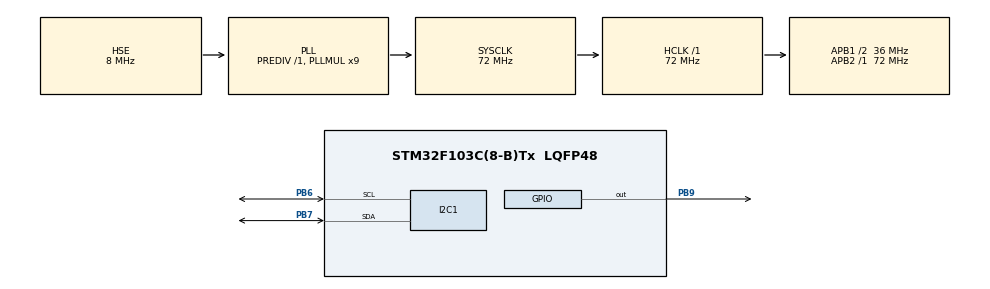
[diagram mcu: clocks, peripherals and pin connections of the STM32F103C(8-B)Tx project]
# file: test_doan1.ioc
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FREERTOS.Tasks01=clock_task,0,128,StartDefaultTask,Default,NULL,Dynamic,NULL,NULL;dht22_task,0,128,StartTask02,Default,NULL,Dynamic,NULL,NULL
I2C1.I2C_Mode=I2C_Fast
Mcu.Family=STM32F1
Mcu.Name=STM32F103C(8-B)Tx
Mcu.Package=LQFP48
NVIC.PriorityGroup=NVIC_PRIORITYGROUP_4
NVIC.TIM4_IRQn=true\:15\:0\:false\:false\:true\:false\:false\:true\:true
NVIC.TimeBase=TIM4_IRQn
NVIC.TimeBaseIP=TIM4
PA13.Mode=Serial_Wire
PA13.Signal=SYS_JTMS-SWDIO
PA14.Mode=Serial_Wire
PA14.Signal=SYS_JTCK-SWCLK
PB6.Mode=I2C
PB6.Signal=I2C1_SCL
PB7.Mode=I2C
PB7.Signal=I2C1_SDA
PB9.Signal=GPIO_Output
PD0-OSC_IN.Mode=HSE-External-Oscillator
PD0-OSC_IN.Signal=RCC_OSC_IN
PD1-OSC_OUT.Mode=HSE-External-Oscillator
PD1-OSC_OUT.Signal=RCC_OSC_OUT
ProjectManager.HeapSize=0x200
ProjectManager.StackSize=0x400
ProjectManager.TargetToolchain=MDK-ARM V5.32
RCC.AHBFreq_Value=72000000
RCC.APB1CLKDivider=RCC_HCLK_DIV2
RCC.APB1Freq_Value=36000000
RCC.APB1TimFreq_Value=72000000
RCC.APB2Freq_Value=72000000
RCC.APB2TimFreq_Value=72000000
RCC.HCLKFreq_Value=72000000
RCC.PLLMUL=RCC_PLL_MUL9
RCC.PLLSourceVirtual=RCC_PLLSOURCE_HSE
RCC.SYSCLKFreq_VALUE=72000000
RCC.SYSCLKSource=RCC_SYSCLKSOURCE_PLLCLK
RCC.USBFreq_Value=72000000
TIM1.Prescaler=71
VP_FREERTOS_VS_CMSIS_V1.Mode=CMSIS_V1
VP_RTC_No_RTC_Output.Mode=RTC_OUT_NO
VP_RTC_VS_RTC_Activate.Mode=RTC_Enabled
VP_RTC_VS_RTC_Calendar.Mode=RTC_Calendar
VP_SYS_VS_tim4.Mode=TIM4
VP_TIM1_VS_ClockSourceINT.Mode=Internal
board=custom

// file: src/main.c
/* USER CODE BEGIN Header */
/**
  ******************************************************************************
  * @file           : main.c
  * @brief          : Main program body
  ******************************************************************************
  * @attention
  *
  * Copyright (c) 2025 STMicroelectronics.
  * All rights reserved.
  *
  * This software is licensed under terms that can be found in the LICENSE file
  * in the root directory of this software component.
  * If no LICENSE file comes with this software, it is provided AS-IS.
  *
  ******************************************************************************
  */
/* USER CODE END Header */
#include "main.h"
#include "cmsis_os.h"
#include "fonts.h"
#include "ssd1306.h"
#include <stdio.h>
/* USER CODE BEGIN Includes */
#define DHT22_PORT GPIOB
#define DHT22_PIN GPIO_PIN_9
/* USER CODE END Includes */

I2C_HandleTypeDef hi2c1;

RTC_HandleTypeDef hrtc;

TIM_HandleTypeDef htim1;

osThreadId clock_taskHandle;
osThreadId dht22_taskHandle;

void SystemClock_Config(void);
static void MX_GPIO_Init(void);
static void MX_I2C1_Init(void);
static void MX_RTC_Init(void);
static void MX_TIM1_Init(void);
void StartDefaultTask(void const * argument);
void StartTask02(void const * argument);
/*--------------------------------------------------------*/
uint8_t RH1, RH2, TC1, TC2, SUM, CHECK;
uint32_t pMillis, cMillis;
float tCelsius = 0;
float RH = 0;
uint8_t RHI, RHD, TCI, TCD;
char strCopy[15];

void microDelay (uint16_t delay)
{
  __HAL_TIM_SET_COUNTER(&htim1, 0);
  while (__HAL_TIM_GET_COUNTER(&htim1) < delay);
}

uint8_t DHT22_Start (void)
{
  uint8_t Response = 0;
  GPIO_InitTypeDef GPIO_InitStructPrivate = {0};
  GPIO_InitStructPrivate.Pin = DHT22_PIN;
  GPIO_InitStructPrivate.Mode = GPIO_MODE_OUTPUT_PP;
  GPIO_InitStructPrivate.Speed = GPIO_SPEED_FREQ_LOW;
  GPIO_InitStructPrivate.Pull = GPIO_NOPULL;
  HAL_GPIO_Init(DHT22_PORT, &GPIO_InitStructPrivate); // set the pin as output
  HAL_GPIO_WritePin (DHT22_PORT, DHT22_PIN, GPIO_PIN_RESET);   // pull the pin low
  microDelay (1300);   // wait for 1300us
  HAL_GPIO_WritePin (DHT22_PORT, DHT22_PIN, GPIO_PIN_SET);   // pull the pin high
  microDelay (30);   // wait for 30us
  GPIO_InitStructPrivate.Mode = GPIO_MODE_INPUT;
  GPIO_InitStructPrivate.Pull = GPIO_PULLUP;
  HAL_GPIO_Init(DHT22_PORT, &GPIO_InitStructPrivate); // set the pin as input
  microDelay (40);
  if (!(HAL_GPIO_ReadPin (DHT22_PORT, DHT22_PIN)))
  {
    microDelay (80);
    if ((HAL_GPIO_ReadPin (DHT22_PORT, DHT22_PIN))) Response = 1;
  }
  pMillis = HAL_GetTick();
  cMillis = HAL_GetTick();
  while ((HAL_GPIO_ReadPin (DHT22_PORT, DHT22_PIN)) && pMillis + 2 > cMillis)
  {
    cMillis = HAL_GetTick();
  }
  return Response;
}

uint8_t DHT22_Read (void)
{
  uint8_t a,b;
  for (a=0;a<8;a++)
  {
    pMillis = HAL_GetTick();
    cMillis = HAL_GetTick();
    while (!(HAL_GPIO_ReadPin (DHT22_PORT, DHT22_PIN)) && pMillis + 2 > cMillis)
    {  // wait for the pin to go high
      cMillis = HAL_GetTick();
    }
    microDelay (40);   // wait for 40 us
    if (!(HAL_GPIO_ReadPin (DHT22_PORT, DHT22_PIN)))   // if the pin is low
      b&= ~(1<<(7-a));
    else
      b|= (1<<(7-a));
    pMillis = HAL_GetTick();
    cMillis = HAL_GetTick();
    while ((HAL_GPIO_ReadPin (DHT22_PORT, DHT22_PIN)) && pMillis + 2 > cMillis)
    {  // wait for the pin to go low
      cMillis = HAL_GetTick();
    }
  }
  return b;
}

int main(void)
{

  /* MCU Configuration--------------------------------------------------------*/

  /* Reset of all peripherals, Initializes the Flash interface and the Systick. */
  HAL_Init();

  /* Configure the system clock */
  SystemClock_Config();

  /* Initialize all configured peripherals */
  MX_GPIO_Init();
  MX_I2C1_Init();
  MX_RTC_Init();
  MX_TIM1_Init();
	SSD1306_Init();

  /* Create the thread(s) */
  /* definition and creation of clock_task */
  osThreadDef(clock_task, StartDefaultTask, osPriorityNormal, 0, 128);
  clock_taskHandle = osThreadCreate(osThread(clock_task), NULL);

  /* definition and creation of dht22_task */
  osThreadDef(dht22_task, StartTask02, osPriorityNormal, 0, 128);
  dht22_taskHandle = osThreadCreate(osThread(dht22_task), NULL);

  /* Start scheduler */
  osKernelStart();

  /* We should never get here as control is now taken by the scheduler */

  /* Infinite loop */
  while (1)
  {

  }
}

void SystemClock_Config(void)
{
  RCC_OscInitTypeDef RCC_OscInitStruct = {0};
  RCC_ClkInitTypeDef RCC_ClkInitStruct = {0};
  RCC_PeriphCLKInitTypeDef PeriphClkInit = {0};

  /** Initializes the RCC Oscillators according to the specified parameters
  * in the RCC_OscInitTypeDef structure.
  */
  RCC_OscInitStruct.OscillatorType = RCC_OSCILLATORTYPE_LSI|RCC_OSCILLATORTYPE_HSE;
  RCC_OscInitStruct.HSEState = RCC_HSE_ON;
  RCC_OscInitStruct.HSEPredivValue = RCC_HSE_PREDIV_DIV1;
  RCC_OscInitStruct.HSIState = RCC_HSI_ON;
  RCC_OscInitStruct.LSIState = RCC_LSI_ON;
  RCC_OscInitStruct.PLL.PLLState = RCC_PLL_ON;
  RCC_OscInitStruct.PLL.PLLSource = RCC_PLLSOURCE_HSE;
  RCC_OscInitStruct.PLL.PLLMUL = RCC_PLL_MUL9;
  if (HAL_RCC_OscConfig(&RCC_OscInitStruct) != HAL_OK)
  {
    Error_Handler();
  }

  /** Initializes the CPU, AHB and APB buses clocks
  */
  RCC_ClkInitStruct.ClockType = RCC_CLOCKTYPE_HCLK|RCC_CLOCKTYPE_SYSCLK
                              |RCC_CLOCKTYPE_PCLK1|RCC_CLOCKTYPE_PCLK2;
  RCC_ClkInitStruct.SYSCLKSource = RCC_SYSCLKSOURCE_PLLCLK;
  RCC_ClkInitStruct.AHBCLKDivider = RCC_SYSCLK_DIV1;
  RCC_ClkInitStruct.APB1CLKDivider = RCC_HCLK_DIV2;
  RCC_ClkInitStruct.APB2CLKDivider = RCC_HCLK_DIV1;

  if (HAL_RCC_ClockConfig(&RCC_ClkInitStruct, FLASH_LATENCY_2) != HAL_OK)
  {
    Error_Handler();
  }
  PeriphClkInit.PeriphClockSelection = RCC_PERIPHCLK_RTC;
  PeriphClkInit.RTCClockSelection = RCC_RTCCLKSOURCE_LSI;
  if (HAL_RCCEx_PeriphCLKConfig(&PeriphClkInit) != HAL_OK)
  {
    Error_Handler();
  }
}

static void MX_I2C1_Init(void)
{

  hi2c1.Instance = I2C1;
  hi2c1.Init.ClockSpeed = 400000;
  hi2c1.Init.DutyCycle = I2C_DUTYCYCLE_2;
  hi2c1.Init.OwnAddress1 = 0;
  hi2c1.Init.AddressingMode = I2C_ADDRESSINGMODE_7BIT;
  hi2c1.Init.DualAddressMode = I2C_DUALADDRESS_DISABLE;
  hi2c1.Init.OwnAddress2 = 0;
  hi2c1.Init.GeneralCallMode = I2C_GENERALCALL_DISABLE;
  hi2c1.Init.NoStretchMode = I2C_NOSTRETCH_DISABLE;
  if (HAL_I2C_Init(&hi2c1) != HAL_OK)
  {
    Error_Handler();
  }

}

static void MX_RTC_Init(void)
{

  RTC_TimeTypeDef sTime = {0};
  RTC_DateTypeDef DateToUpdate = {0};

  /** Initialize RTC Only
  */
  hrtc.Instance = RTC;
  hrtc.Init.AsynchPrediv = RTC_AUTO_1_SECOND;
  hrtc.Init.OutPut = RTC_OUTPUTSOURCE_NONE;
  if (HAL_RTC_Init(&hrtc) != HAL_OK)
  {
    Error_Handler();
  }

  /** Initialize RTC and set the Time and Date
  */
	  sTime.Hours = 0x14;
  sTime.Minutes = 0x03;
  sTime.Seconds = 0x0;

  if (HAL_RTC_SetTime(&hrtc, &sTime, RTC_FORMAT_BCD) != HAL_OK)
  {
    Error_Handler();
  }
  DateToUpdate.WeekDay = RTC_WEEKDAY_MONDAY;
  DateToUpdate.Month = RTC_MONTH_JANUARY;
  DateToUpdate.Date = 0x1;
  DateToUpdate.Year = 0x0;

  if (HAL_RTC_SetDate(&hrtc, &DateToUpdate, RTC_FORMAT_BCD) != HAL_OK)
  {
    Error_Handler();
  }

}

static void MX_TIM1_Init(void)
{

  TIM_ClockConfigTypeDef sClockSourceConfig = {0};
  TIM_MasterConfigTypeDef sMasterConfig = {0};

  htim1.Instance = TIM1;
  htim1.Init.Prescaler = 71;
  htim1.Init.CounterMode = TIM_COUNTERMODE_UP;
  htim1.Init.Period = 65535;
  htim1.Init.ClockDivision = TIM_CLOCKDIVISION_DIV1;
  htim1.Init.RepetitionCounter = 0;
  htim1.Init.AutoReloadPreload = TIM_AUTORELOAD_PRELOAD_DISABLE;
  if (HAL_TIM_Base_Init(&htim1) != HAL_OK)
  {
    Error_Handler();
  }
  sClockSourceConfig.ClockSource = TIM_CLOCKSOURCE_INTERNAL;
  if (HAL_TIM_ConfigClockSource(&htim1, &sClockSourceConfig) != HAL_OK)
  {
    Error_Handler();
  }
  sMasterConfig.MasterOutputTrigger = TIM_TRGO_RESET;
  sMasterConfig.MasterSlaveMode = TIM_MASTERSLAVEMODE_DISABLE;
  if (HAL_TIMEx_MasterConfigSynchronization(&htim1, &sMasterConfig) != HAL_OK)
  {
    Error_Handler();
  }

}

static void MX_GPIO_Init(void)
{
  GPIO_InitTypeDef GPIO_InitStruct = {0};

  /* GPIO Ports Clock Enable */
  __HAL_RCC_GPIOD_CLK_ENABLE();
  __HAL_RCC_GPIOA_CLK_ENABLE();
  __HAL_RCC_GPIOB_CLK_ENABLE();

  /*Configure GPIO pin Output Level */
  HAL_GPIO_WritePin(GPIOB, GPIO_PIN_9, GPIO_PIN_RESET);

  /*Configure GPIO pin : PB9 */
  GPIO_InitStruct.Pin = GPIO_PIN_9;
  GPIO_InitStruct.Mode = GPIO_MODE_OUTPUT_PP;
  GPIO_InitStruct.Pull = GPIO_NOPULL;
  GPIO_InitStruct.Speed = GPIO_SPEED_FREQ_LOW;
  HAL_GPIO_Init(GPIOB, &GPIO_InitStruct);

}

/* USER CODE BEGIN 4 */
void StartDefaultTask(void const * argument)
{
  RTC_TimeTypeDef sTime;
  RTC_DateTypeDef sDate;
  char timeStr[20];

  for(;;)
  {
    HAL_RTC_GetTime(&hrtc, &sTime, RTC_FORMAT_BIN);
    HAL_RTC_GetDate(&hrtc, &sDate, RTC_FORMAT_BIN); // Ph?i g?i d? clear flag RTC

    sprintf(timeStr, "Time:%02d:%02d", sTime.Hours, sTime.Minutes);

    SSD1306_GotoXY(0, 0); // Dòng d?u tiên
		SSD1306_ClearArea(0, 0, 128, 15);
    SSD1306_Puts(timeStr,&Font_11x18, SSD1306_COLOR_WHITE);
    SSD1306_UpdateScreen();

    osDelay(60000);
  }
}
void StartTask02(void const * argument)
{

  HAL_TIM_Base_Start(&htim1); // Timer d? t?o microDelay

  for(;;)
  {
    if(DHT22_Start())
    {
      RH1 = DHT22_Read();
      RH2 = DHT22_Read();
      TC1 = DHT22_Read();
      TC2 = DHT22_Read();
      SUM = DHT22_Read();
      CHECK = RH1 + RH2 + TC1 + TC2;

      if (CHECK == SUM)
      {
        if (TC1>127) // If TC1=10000000, negative temperature
        {
          tCelsius = (float)TC2/10*(-1);
        }
        else
        {
          tCelsius = (float)((TC1<<8)|TC2)/10;
        }

        RH = (float) ((RH1<<8)|RH2)/10;
        SSD1306_GotoXY (0, 20);
        RHI = RH;  // Relative humidity integral
        RHD = RH*10-RHI*10; // Relative humidity decimal
        sprintf(strCopy,"Hump:%d.%d %%  ", RHI, RHD);
        SSD1306_Puts (strCopy, &Font_11x18, SSD1306_COLOR_WHITE);
        SSD1306_GotoXY (0, 40);
        if (tCelsius < 0)
        {
          TCI = tCelsius *(-1);  // Celsius integral
          TCD = tCelsius*(-10)-TCI*10; // Celsius decimal
          sprintf(strCopy,"Temp:-%d.%d C   ", TCI, TCD);
        }
        else
        {
          TCI = tCelsius;  // Celsius integral
          TCD = tCelsius*10-TCI*10; // Celsius decimal
          sprintf(strCopy,"Temp:%d.%d C   ", TCI, TCD);
        }

        SSD1306_Puts (strCopy, &Font_11x18, SSD1306_COLOR_WHITE);
        SSD1306_UpdateScreen();
      }
    }

    osDelay(2000);
  }
}
/* USER CODE END 4 */

void HAL_TIM_PeriodElapsedCallback(TIM_HandleTypeDef *htim)
{
  if (htim->Instance == TIM4) {
    HAL_IncTick();
  }
}

void Error_Handler(void)
{
  __disable_irq();
  while (1)
  {
  }
}
